# cslr_timergpc5510_001 register map
Vendor: Texas Instruments
Peripheral module from a debugger description file.
Registers are 16-bit, access per field, no defined reset value unless marked. A register's access mark holds for its fields unless they carry their own. Offsets are as the file gives them; lines under a group give offsets from that group; [hi:lo] are bit positions; {n}, {i} and the like mark numbered series; 'fields as' and 'values as' point back to an identical list; <NAME> marks a mode.

## Timer,_GP — Timer, general-purpose
0x00 TIM ro — Main count register
  [15:0] TIM — Main count register.
0x01 PRD rw — Main period register
  [15:0] PRD — Main period register.
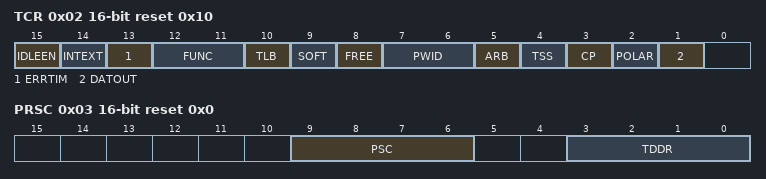
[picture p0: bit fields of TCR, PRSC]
0x02 TCR reset 0x10 — Timer control register
  [15] IDLEEN rw — Idle enable bit for the timer.
    0=The timer cannot be placed in an idle state; 1=If the PERIPH domain is idle (PERIS = 1 in the idle status register), the timer is stopped in a low-power state
  [14] INTEXT ro — Internal-to-external clock change indicator.
    0=Timer not ready to use an external clock source; 1=Timer ready to use an external clock source
  [13] ERRTIM ro — Timer-pin error flag.
    0=No error detected or ERRTIM has been read; 1=Error detected in a write to the FUNC bits
  [12:11] FUNC rw — Function bits for the timer pin.
    0=00b (Pin Function: None.); 1=01b (Pin Function: Timer output.); 2=10b (Pin Function: General-purpose output.); 3=11b (Pin Function: External clock input.)
  [10] TLB rw — Timer load bit.
    0=When TLB = 0, TIM and PSC are not being loaded; 1=Until TLB = 0, load TIM from PRD, and load PSC from TDDR
  [9] SOFT rw — 0
    0=Hard stop; 1=Soft stop
  [8] FREE rw — Free run bit.
    0=The timer is affected as determined by the SOFT bit; 1=Free run
  [7:6] PWID rw — Timer-output pulse width bit.
    0=00b (1 CPU clock period); 1=01b (2 CPU clock periods); 2=10b (4 CPU clock periods); 3=11b (8 CPU clock periods)
  [5] ARB rw — Auto-reload bit.
    0=ARB has been cleared; 1=Each time TIM reaches 0, reload TIM from PRD, and reload PSC from TDDR
  [4] TSS rw — Timer stop status bit.
    0=Start the timer; 1=Stop the timer. (Reset condition)
  [3] CP rw — Clock mode/pulse mode bit.
    0=Pulse mode; 1=Clock mode
  [2] POLAR rw — Timer-output polarity bit.
    0=The signal on the timer pin starts low; 1=The signal on the timer pin starts high
  [1] DATOUT rw — Data output bit.
    0=Drive the signal on the timer pin low; 1=Drive the signal on the timer pin high
0x03 PRSC reset 0x0 — Timer prescaler register
  [9:6] PSC ro — Prescaler count register.
  [3:0] TDDR rw — Timer divide-down register (prescaler period register).
